# ADSP-2183xW_LPC register map
Vendor: Analog Devices; Series: ADSP-2183xW_LPC; File version: 3.0.3.517
CPU: 
Registers are 32-bit, read-write, reset 0x0 unless marked. A register's access mark holds for its fields unless they carry their own. Offsets are from the block's base; [hi:lo] are bit positions; 'fields as' and 'values as' point back to an identical list.

## STM0 — CoreSight STM
Base 0x31104000
0xC04 STMDMASTARTR — DMA Transfer Start Register
  [0] START wo range 0x00000000..0x00000001
0xC08 STMDMASTOPR — DMA Transfer Stop Register
  [0] STOP wo range 0x00000000..0x00000001
0xC0C STMDMASTATR — DMA Transfer Status Register
  [0] STATUS ro
0xC10 STMDMACTLR — DMA Control Register
  [3:2] SENS range 0x00000000..0x00000003 — Sensitivity
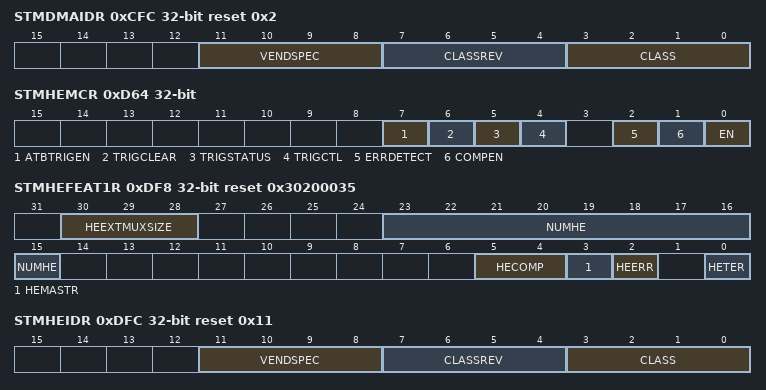
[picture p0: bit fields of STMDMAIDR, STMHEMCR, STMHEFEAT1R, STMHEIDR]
0xCFC STMDMAIDR reset 0x2 — DMA features ID Register
  [11:8] VENDSPEC ro — Vendor specific
  [7:4] CLASSREV ro — Class revision
  [3:0] CLASS ro
0xD00 STMHEER — Hardware Event Enable Register
  [31:0] HEE range 0x00000000..0xFFFFFFFF — Hardware event enable
0xD20 STMHETER — Hardware Event Trigger Enable Register
  [31:0] HETE range 0x00000000..0xFFFFFFFF — Hardware event trigger enable
0xD60 STMHEBSR — Hardware Event Bank Select Register
  [0] HEBS range 0x00000000..0x00000001 — Hardware event bank select
0xD64 STMHEMCR — Hardware Event Main Control Register
  [7] ATBTRIGEN range 0x00000000..0x00000001 — ATB trigger enable
  [6] TRIGCLEAR wo range 0x00000000..0x00000001 — Trigger clear
  [5] TRIGSTATUS ro — Trigger status
  [4] TRIGCTL range 0x00000000..0x00000001 — Trigger Control
  [2] ERRDETECT ro — Error Detection Enable
  [1] COMPEN range 0x00000000..0x00000001 — Compression Enable
  [0] EN range 0x00000000..0x00000001 — HE enable
0xD68 STMHEEXTMUXR — Hardware Event External Multiplex Control Register
  [7:0] EXTMUX range 0x00000000..0x000000FF — External Multiplex Control
0xDF4 STMHEMASTR reset 0x80 — Hardware Event Master Number Register
  [15:0] MASTER ro — Hardware event STPv2 master number
0xDF8 STMHEFEAT1R reset 0x30200035 — Hardware Event Features 1 Register
  [30:28] HEEXTMUXSIZE ro — HW Event external multiplex size
  [23:15] NUMHE ro — The number of hardware events
  [5:4] HECOMP ro — Data compression
  [3] HEMASTR ro — STMHEMASTR support
  [2] HEERR ro — Error detection support
  [0] HETER ro — STMHETER support
0xDFC STMHEIDR reset 0x11 — Hardware Event Features ID Register
  fields as STMDMAIDR
0xE00 STMSPER — Stimulus Port Enable Register
  [31:0] SPE range 0x00000000..0xFFFFFFFF — Stimulus port enable
0xE20 STMSPTER — Stimulus Port Trigger Enable Register
  [31:0] SPTE range 0x00000000..0xFFFFFFFF — Stimulus port trigger enable
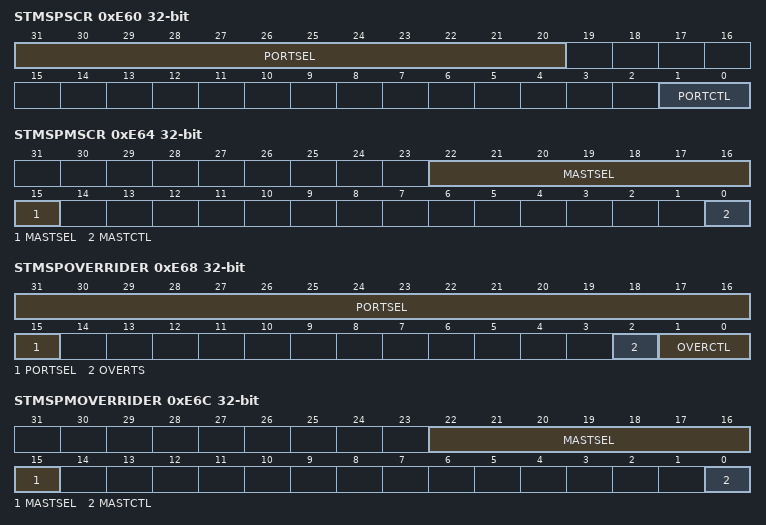
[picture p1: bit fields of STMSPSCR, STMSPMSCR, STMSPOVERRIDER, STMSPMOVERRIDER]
0xE60 STMSPSCR — Stimulus Port Select Configuration Register
  [31:20] PORTSEL range 0x00000000..0x00000FFF — Port Selection
  [1:0] PORTCTL range 0x00000000..0x00000003 — Port selection control
0xE64 STMSPMSCR — Stimulus Port Master Select Configuration Register
  [22:15] MASTSEL range 0x00000000..0x000000FF — Master Selection
  [0] MASTCTL range 0x00000000..0x00000001 — Master selection control
0xE68 STMSPOVERRIDER — Stimulus Port Override Control Register
  [31:15] PORTSEL range 0x00000000..0x0001FFFF — Port Selection
  [2] OVERTS range 0x00000000..0x00000001 — Timestamping override
  [1:0] OVERCTL range 0x00000000..0x00000003 — Override control
0xE6C STMSPMOVERRIDER — Stimulus Port Master Override Control Register
  [22:15] MASTSEL range 0x00000000..0x000000FF — Master Selection
  [0] MASTCTL range 0x00000000..0x00000001 — Override control
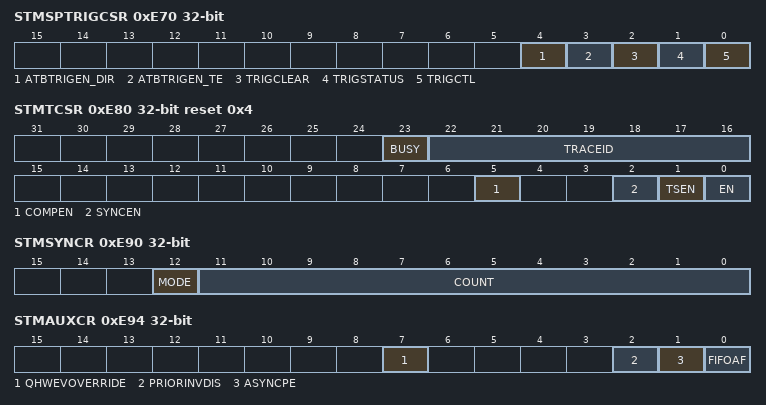
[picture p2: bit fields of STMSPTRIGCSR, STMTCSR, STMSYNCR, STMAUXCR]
0xE70 STMSPTRIGCSR — Stimulus Port Trigger Control and Status Register
  [4] ATBTRIGEN_DIR range 0x00000000..0x00000001 — ATB trigger enable
  [3] ATBTRIGEN_TE range 0x00000000..0x00000001 — ATB trigger enable
  [2] TRIGCLEAR wo range 0x00000000..0x00000001 — Trigger clear
  [1] TRIGSTATUS ro — Trigger status
  [0] TRIGCTL range 0x00000000..0x00000001 — Trigger Control
0xE80 STMTCSR reset 0x4 — Trace Control and Status Register
  [23] BUSY ro
  [22:16] TRACEID range 0x00000000..0x0000007F
  [5] COMPEN range 0x00000000..0x00000001 — Compression Enable for Stimulus Ports
  [2] SYNCEN ro — Synchronization Enable
  [1] TSEN range 0x00000000..0x00000001 — Enable timestamping
  [0] EN range 0x00000000..0x00000001 — STM enable
0xE84 STMTSSTIMR — Timestamp Stimulus Register
  [0] FORCETS wo range 0x00000000..0x00000001 — Force timestamp
0xE8C STMTSFREQR — Timestamp Frequency Register
  [31:0] FREQ range 0x00000000..0xFFFFFFFF — Timestamp frequency
0xE90 STMSYNCR — Synchronization Control Register
  [12] MODE range 0x00000000..0x00000001 — Mode control
  [11:0] COUNT range 0x00000000..0x00000FFF — Counter value
0xE94 STMAUXCR — Auxiliary Control Register
  [7] QHWEVOVERRIDE range 0x00000000..0x00000001 — Q-Channel Hardware Event override
  [2] PRIORINVDIS range 0x00000000..0x00000001 — Priority inversion disable during flush
  [1] ASYNCPE range 0x00000000..0x00000001 — ASYNC Priority escalation
  [0] FIFOAF range 0x00000000..0x00000001 — FIFO Auto-Flush
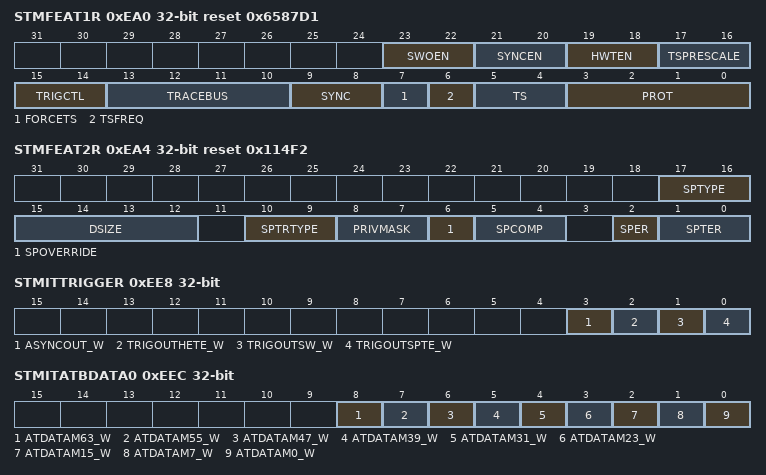
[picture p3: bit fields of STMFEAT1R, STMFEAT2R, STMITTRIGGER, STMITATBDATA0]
0xEA0 STMFEAT1R reset 0x6587D1 — STM Features 1 Register
  [23:22] SWOEN ro — STMTCSR.SWOEN support
  [21:20] SYNCEN ro — STMTCSR.SYNCEN support
  [19:18] HWTEN ro — STMTCSR.HWTEN support
  [17:16] TSPRESCALE ro — Timestamp prescale support:
  [15:14] TRIGCTL ro — Trigger control support
  [13:10] TRACEBUS ro — Trace bus support
  [9:8] SYNC ro — STMSYNCR support
  [7] FORCETS ro — STMTSSTIMR support
  [6] TSFREQ ro — Timestamp frequency indication
  [5:4] TS ro — Timestamp support
  [3:0] PROT ro — Protocol
0xEA4 STMFEAT2R reset 0x114F2 — STM Features 2 Register
  [17:16] SPTYPE ro — Stimulus Port Type support
  [15:12] DSIZE ro — Fundamental data size
  [10:9] SPTRTYPE ro — Stimulus Port Transaction Type support
  [8:7] PRIVMASK ro — STMPRIVMASKR support
  [6] SPOVERRIDE ro — STMOVERRIDER support
  [5:4] SPCOMP ro — Data compression on stimulus ports support.
  [2] SPER ro — STMSPER presence
  [1:0] SPTER ro — STMSPTER support
0xEA8 STMFEAT3R reset 0x7F — STM Features 3 Register
  [6:0] NUMMAST ro — Number of Masters
0xEE8 STMITTRIGGER — Integration Test for Cross-Trigger Outputs Register
  [3] ASYNCOUT_W wo range 0x00000000..0x00000001 — ASYNCOUT
  [2] TRIGOUTHETE_W wo range 0x00000000..0x00000001 — TRIGOUTHETE
  [1] TRIGOUTSW_W wo range 0x00000000..0x00000001 — TRIGOUTSW
  [0] TRIGOUTSPTE_W wo range 0x00000000..0x00000001 — TRIGOUTSPTE
0xEEC STMITATBDATA0 — Integration Mode ATB Data 0 Register
  [8] ATDATAM63_W wo range 0x00000000..0x00000001 — ATDATAM63
  [7] ATDATAM55_W wo range 0x00000000..0x00000001 — ATDATAM55
  [6] ATDATAM47_W wo range 0x00000000..0x00000001 — ATDATAM47
  [5] ATDATAM39_W wo range 0x00000000..0x00000001 — ATDATAM39
  [4] ATDATAM31_W wo range 0x00000000..0x00000001 — ATDATAM31
  [3] ATDATAM23_W wo range 0x00000000..0x00000001 — ATDATAM23
  [2] ATDATAM15_W wo range 0x00000000..0x00000001 — ATDATAM15
  [1] ATDATAM7_W wo range 0x00000000..0x00000001 — ATDATAM7
  [0] ATDATAM0_W wo range 0x00000000..0x00000001 — ATDATAM0
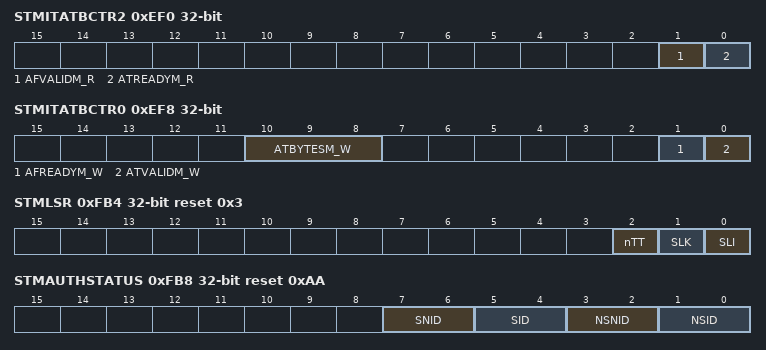
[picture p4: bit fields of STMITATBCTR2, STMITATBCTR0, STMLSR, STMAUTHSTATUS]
0xEF0 STMITATBCTR2 — Integration Mode ATB Control 2 Register
  [1] AFVALIDM_R ro — AFVALIDM
  [0] ATREADYM_R ro — ATREADYM
0xEF4 STMITATBID — Integration Mode ATB Identification Register
  [6:0] ATIDM_W wo range 0x00000000..0x0000007F — ATIDM
0xEF8 STMITATBCTR0 — Integration Mode ATB Control 0 Register
  [10:8] ATBYTESM_W wo range 0x00000000..0x00000007 — ATBYTESM
  [1] AFREADYM_W wo range 0x00000000..0x00000001 — AFREADYM
  [0] ATVALIDM_W wo range 0x00000000..0x00000001 — ATVALIDM
0xF00 STMITCTRL — Integration Mode Control Register
  [0] IME range 0x00000000..0x00000001 — Integration Mode
0xFA0 STMCLAIMSET reset 0xF — Claim Tag Set Register
  [3:0] SET_R ro — Claim Tag Implemented
  [3:0] SET_W wo range 0x00000000..0x0000000F — Set Claim Tag
0xFA4 STMCLAIMCLR — Claim Tag Clear Register
  [3:0] CLR_R ro — Claim Tag Value
  [3:0] CLR_W wo range 0x00000000..0x0000000F — Clear Claim Tag
0xFB0 STMLAR — Lock Access Register
  [31:0] KEY wo range 0x00000000..0xFFFFFFFF — Write Access Code
0xFB4 STMLSR reset 0x3 — Lock Status Register
  [2] nTT ro — Lock Access size
  [1] SLK ro — Lock Setting
  [0] SLI ro — Lock present
0xFB8 STMAUTHSTATUS reset 0xAA — Authentication Status Register
  [7:6] SNID ro — Secure Non-Invasive Debug
  [5:4] SID ro — Secure Inasive Debug
  [3:2] NSNID ro — Non-Secure Non-Invasive Debug
  [1:0] NSID ro — Non-Secure Inasive Debug
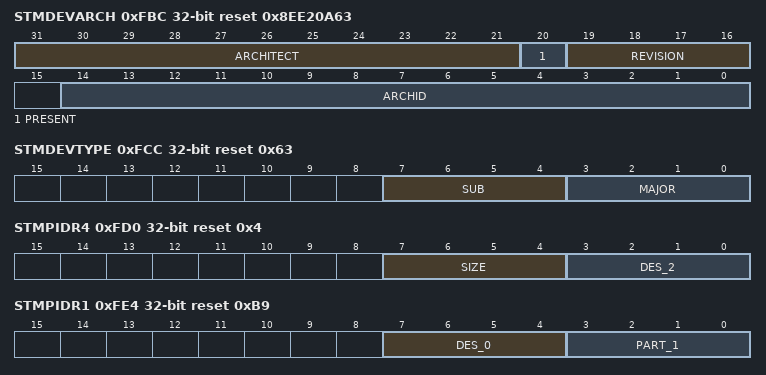
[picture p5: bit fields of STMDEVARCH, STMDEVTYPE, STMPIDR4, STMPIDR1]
0xFBC STMDEVARCH reset 0x8EE20A63 — Device Architecture Register
  [31:21] ARCHITECT ro
  [20] PRESENT ro
  [19:16] REVISION ro
  [14:0] ARCHID ro — Architecture ID
0xFC8 STMDEVID reset 0x10000 — Device Configuration Register
  [16:0] NUMSP ro — The number of stimulus ports implemented
0xFCC STMDEVTYPE reset 0x63 — Device Type Identifier Register
  [7:4] SUB ro, [3:0] MAJOR ro
0xFD0 STMPIDR4 reset 0x4 — Peripheral ID4 Register
  [7:4] SIZE ro — 4KB count
  [3:0] DES_2 ro — JEP106 continuation code,
0xFE0 STMPIDR0 reset 0x63 — Peripheral ID0 Register
  [7:0] PART_0 ro — Part Number [7:0]
0xFE4 STMPIDR1 reset 0xB9 — Peripheral ID1 Register
  [7:4] DES_0 ro — JEP106 identity code [3:0]
  [3:0] PART_1 ro — Part Number [11:8]
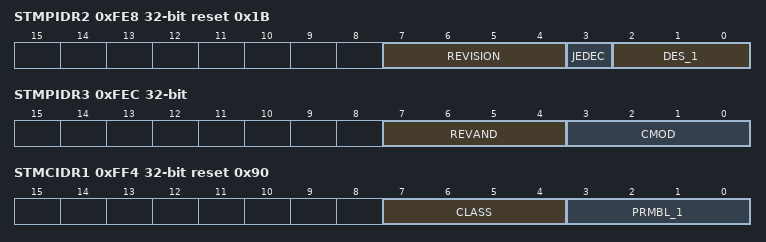
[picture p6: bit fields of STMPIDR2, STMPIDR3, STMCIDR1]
0xFE8 STMPIDR2 reset 0x1B — Peripheral ID2 Register
  [7:4] REVISION ro
  [3] JEDEC ro
  [2:0] DES_1 ro — JEP106 identity code [6:4]
0xFEC STMPIDR3 — Peripheral ID3 Register
  [7:4] REVAND ro
  [3:0] CMOD ro — Customer Modified
0xFF0 STMCIDR0 reset 0xD — Component ID0 Register
  [7:0] PRMBL_0 ro — Preamble
0xFF4 STMCIDR1 reset 0x90 — Component ID1 Register
  [7:4] CLASS ro — Component Class
  [3:0] PRMBL_1 ro — Preamble
0xFF8 STMCIDR2 reset 0x5 — Component ID2 Register
  [7:0] PRMBL_2 ro — Preamble
0xFFC STMCIDR3 reset 0xB1 — Component ID3 Register
  [7:0] PRMBL_3 ro — Preamble
